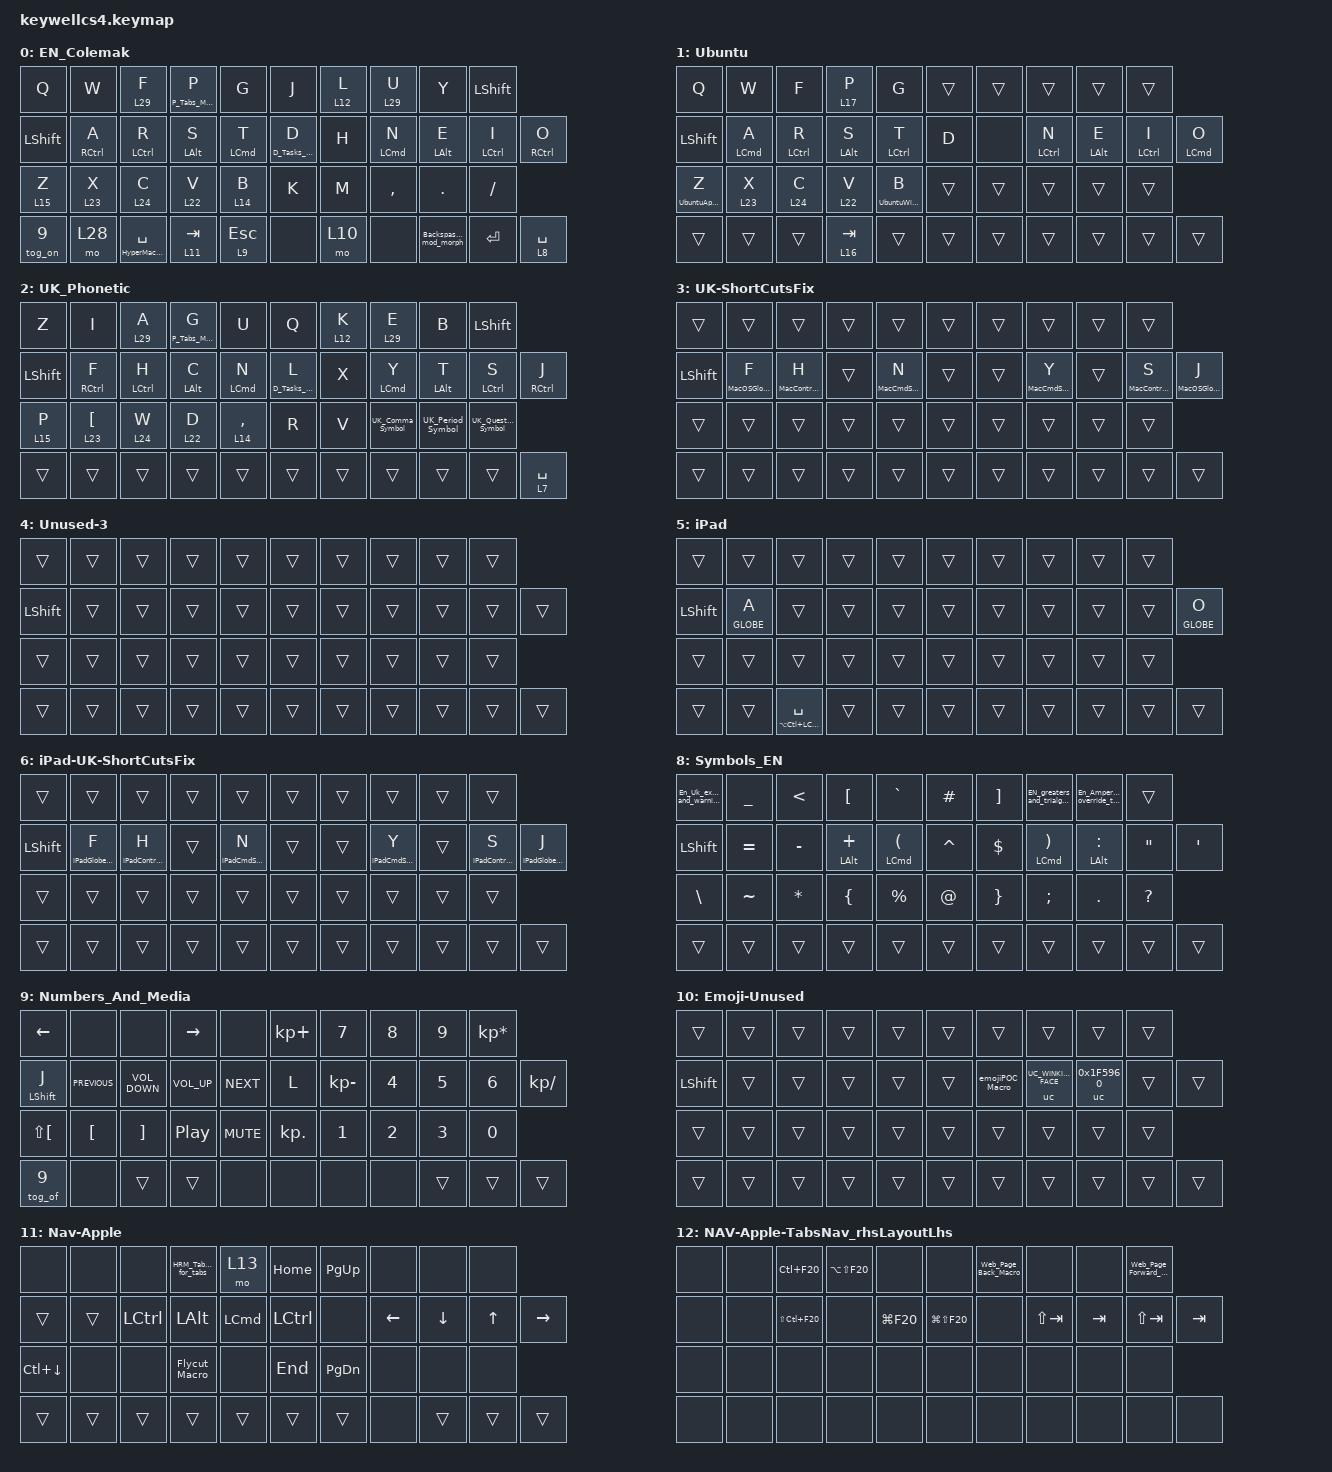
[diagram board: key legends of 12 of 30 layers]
/*
 * Copyright (c) 2020 The ZMK Contributors
 *
 * SPDX-License-Identifier: MIT
 */
// #include <dt-bindings/zmk/rgb.h>
// rob"s zmk unicode

#include <behaviors/unicode.dtsi>

/* MEH...
    Keycodes for other locales
    Gives nothing extra except key representation in visual editor
    https://github.com/nickcoutsos/keymap-editor/wiki/Keycodes-for-other-locales
*/
// #include "includes/keys_uk_enhanced.h"

#define DEFAULT 0
#define SYMBOLS_LAYER  1
#define WARP  22
#define PRESISION  23

#include "includes/mouse.dtsi"
#include <zmk-unicode/keys-extra.h> // All Unicode glyphs except CJK
#include <behaviors.dtsi>
#include <dt-bindings/zmk/bt.h>
#include <dt-bindings/zmk/keys.h>
#include <dt-bindings/zmk/outputs.h>
#include <dt-bindings/zmk/pointing.h>

// rob"s zmk unicode

&uc {
    default-mode = <UC_MODE_MACOS>;
    minimum-length = <4>;
    macos-key = <LALT>;

    // linux-key = <LC(LS(U))>;
    // win-compose-key = <RALT>;
};

/ {
    behaviors {
        #include "includes/open_app_tap_dances.dtsi"

        hml: hml {
            compatible = "zmk,behavior-hold-tap";
            label = "HML";
            bindings = <&kp>, <&kp>;

            #binding-cells = <2>;
            flavor = "balanced";
            tapping-term-ms = <280>;
            quick-tap-ms = <175>;
            require-prior-idle-ms = <150>;
            hold-trigger-key-positions = <5 6 7 8 9 15 16 17 18 19 25 26 27 28 29 30 31 32 33 34 35 36 39 37 38 37 38 40 41 20>;
            hold-trigger-on-release;
        };

        hmr: hmr {
            compatible = "zmk,behavior-hold-tap";
            label = "HMR";
            bindings = <&kp>, <&kp>;

            #binding-cells = <2>;
            flavor = "balanced";
            tapping-term-ms = <280>;
            quick-tap-ms = <175>;
            require-prior-idle-ms = <150>;
            hold-trigger-on-release;
            hold-trigger-key-positions = <0 1 2 3 4 10 11 12 13 14 21 22 23 24 31 32 33 34 35 36 37 38 39 40 41 25 15>;
        };

        Layer_Tap_Timeless_Left: Layer_Tap_Timeless_Left {
            compatible = "zmk,behavior-hold-tap";
            label = "LAYER_TAP_TIMELESS_LEFT";
            bindings = <&mo>, <&kp>;

            #binding-cells = <2>;
            flavor = "balanced";
            tapping-term-ms = <280>;
            quick-tap-ms = <175>;
            require-prior-idle-ms = <150>;
            hold-trigger-on-release;
            hold-trigger-key-positions = <5 6 7 8 9 16 17 18 19 20 26 27 28 29 30 36 37 38 39 40 41 14 11 12 13>;
        };

        Backspase_MacLike_mod_morph: maclike_backspace_delete {
            compatible = "zmk,behavior-mod-morph";
            #binding-cells = <0>;
            bindings = <&kp BACKSPACE>, <&kp DELETE>;

            mods = <(MOD_LSFT)>;   // when LEFT_SHIFT is held
            keep-mods = <0>;       // don't send Shift with Delete
        };

        UK_Period_Symbol: UK_Period_Symbol {
            // Keep it consistent with EN first register only. Second  - ppo.

            compatible = "zmk,behavior-mod-morph";
            label = "UK_PERIOD_SYMBOL";
            bindings = <&kp SLASH>, <&none>;

            #binding-cells = <0>;
            keep-mods = <(MOD_LCTL | MOD_LSFT | MOD_LALT | MOD_LGUI)>;
            mods = <(MOD_RSFT | MOD_LSFT)>;
        };

        UK_Comma_Symbol: UK_Comma_Symbol {
            //  Keep it consistent with EN first register only. Second  - ppo

            compatible = "zmk,behavior-mod-morph";
            label = "UK_COMMA_SYMBOL";
            bindings = <&kp LS(SLASH)>, <&none>;

            #binding-cells = <0>;
            keep-mods = <(MOD_LCTL | MOD_LALT | MOD_LGUI | MOD_LSFT)>;
            mods = <(MOD_LCTL)>;
        };

        UK_Question_Symbol: UK_Question_Symbol {
            //  Keep it consistent with EN 1st and 2nd registers

            compatible = "zmk,behavior-mod-morph";
            label = "UK_QUESTION_SYMBOL";
            bindings = <&kp LC(LA(SLASH))>, <&kp LA(NUMBER_7)>;

            #binding-cells = <0>;
            mods = <(MOD_LSFT | MOD_RSFT)>;
        };

        kt_on: key_toggle_on_only {
            compatible = "zmk,behavior-key-toggle";
            #binding-cells = <1>;
            toggle-mode = "on";   // only presses, never releases
        };

        kt_off: key_toggle_off_only {
            compatible = "zmk,behavior-key-toggle";
            #binding-cells = <1>;
            toggle-mode = "off";  // only releases, never presses
        };

        tog_on: toggle_layer_on_only {
            compatible = "zmk,behavior-toggle-layer";
            #binding-cells = <1>;
            display-name = "Toggle Layer On";
            toggle-mode = "on";
        };

        tog_of: toggle_layer_of_only {
            compatible = "zmk,behavior-toggle-layer";
            #binding-cells = <1>;
            display-name = "Toggle Layer On";
            toggle-mode = "off";
        };

        HyperMac_HT_Timeless: holdTapMacroKp {
            compatible = "zmk,behavior-hold-tap";
            label = "Hyper";
            bindings = <&HyperMacTimeless_Macro>, <&kp>;

            #binding-cells = <2>;
            tapping-term-ms = <173>;
            hold-trigger-key-positions = <0 1 2 3 4 5 6 7 8 9 10 11 12 13 14 15 16 17 18 19 20 21 22 23 24 25 26 27 28 29 30 31 32 33 34 35 36 37 38 39 40 41>;
        };

        MacOS_CMD_non_en_fix_LHRM: MacOS_CMD_non_en_fix_LHRM {
            compatible = "zmk,behavior-hold-tap";
            label = "MACOS_CMD_NON_EN_FIX_LHRM";
            bindings = <&MacCmdShortcutsNonEN_WA_Macro>, <&kp>;

            #binding-cells = <2>;
            flavor = "balanced";
            tapping-term-ms = <180>;
            quick-tap-ms = <175>;
            require-prior-idle-ms = <150>;
            hold-trigger-on-release;
            hold-trigger-key-positions = <5 6 7 8 15 16 17 18 25 26 27 28 36 37 38 39 40 41 30 31 32 33 34 35 9 19 29>;
        };

        MacOS_CMD_non_en_fix_RHRM: MacOS_CMD_non_en_fix_RHRM {
            compatible = "zmk,behavior-hold-tap";
            label = "MACOS_CMD_NON_EN_FIX_RHRM";
            bindings = <&MacCmdShortcutsNonEN_WA_Macro>, <&kp>;

            #binding-cells = <2>;
            flavor = "balanced";
            tapping-term-ms = <180>;
            quick-tap-ms = <175>;
            require-prior-idle-ms = <150>;
            hold-trigger-on-release;
            hold-trigger-key-positions = <0 1 2 3 4 10 11 12 13 14 21 22 23 24 31 32 33 34 35 36 37 38 39 40 41 30 25 15 20>;
        };

        MacOS_Control_non_en_fix_LHRM: MacOS_Control_non_en_fix_LHRM {
            compatible = "zmk,behavior-hold-tap";
            label = "MACOS_CONTROL_NON_EN_FIX_LHRM";
            #binding-cells = <2>;
            flavor = "balanced";
            tapping-term-ms = <180>;
            quick-tap-ms = <175>;
            require-prior-idle-ms = <150>;
            hold-trigger-on-release;
            hold-trigger-key-positions = <5 6 7 8 15 16 17 18 25 26 27 28 36 37 38 39 40 41 30 31 32 33 34 35 9 19 29>;
            bindings = <&MacControlShrtctNonEN_WA_Macro>, <&kp>;
        };

        MacOS_Control_non_en_fix_RHRM: MacOS_Control_non_en_fix_RHRM {
            compatible = "zmk,behavior-hold-tap";
            label = "MACOS_CONTROL_NON_EN_FIX_RHRM";
            #binding-cells = <2>;
            flavor = "balanced";
            tapping-term-ms = <180>;
            quick-tap-ms = <175>;
            require-prior-idle-ms = <150>;
            hold-trigger-on-release;
            bindings = <&MacControlShrtctNonEN_WA_Macro>, <&kp>;

            hold-trigger-key-positions = <0 1 2 3 4 10 11 12 13 14 20 21 22 23 24 30 31 32 33 34 35 36 37 38 39 40 41>;
        };

        iOS_CMD_non_qwerty_fix_LHRM: iOS_CMD_non_qwerty_fix_LHRM {
            compatible = "zmk,behavior-hold-tap";
            label = "IOS_CMD_NON_QWERTY_FIX_LHRM";
            #binding-cells = <2>;
            flavor = "balanced";
            tapping-term-ms = <180>;
            quick-tap-ms = <175>;
            require-prior-idle-ms = <150>;
            hold-trigger-on-release;
            hold-trigger-key-positions = <5 6 7 8 15 16 17 18 25 26 27 28 36 37 38 39 40 41 30 31 32 33 34 35 9 19 29 5>;
            bindings = <&iPadCmdShortcutsNonQwerty_WA>, <&kp>;
        };

        iOS_CMD_non_qwerty_fix_RHRM: iOS_CMD_non_qwerty_fix_RHRM {
            compatible = "zmk,behavior-hold-tap";
            label = "IOS_CMD_NON_QWERTY_FIX_RHRM";
            #binding-cells = <2>;
            flavor = "balanced";
            tapping-term-ms = <180>;
            quick-tap-ms = <175>;
            require-prior-idle-ms = <150>;
            hold-trigger-on-release;
            bindings = <&iPadCmdShortcutsNonQwerty_WA>, <&kp>;

            hold-trigger-key-positions = <0 1 2 3 4 10 11 12 13 14 20 21 22 23 24 30 31 32 33 34 35 36 37 38 39 40 41>;
        };

        iOS_Control_non_qwerty_fix_LHRM: iOS_Control_non_qwerty_fix_LHRM {
            compatible = "zmk,behavior-hold-tap";
            label = "IOS_CONTROL_NON_QWERTY_FIX_LHRM";
            #binding-cells = <2>;
            flavor = "balanced";
            tapping-term-ms = <180>;
            quick-tap-ms = <175>;
            require-prior-idle-ms = <150>;
            hold-trigger-on-release;
            bindings = <&iPadControlShortcutNonQwerty_WA>, <&kp>;

            hold-trigger-key-positions = <5 6 7 8 9 15 16 17 18 19 25 26 27 28 29 36 37 38 39 40 41 30 31 32 33 34 35>;
        };

        iOS_Control_non_qwerty_fix_RHRM: iOS_Control_non_qwerty_fix_RHRM {
            compatible = "zmk,behavior-hold-tap";
            label = "IOS_CONTROL_NON_QWERTY_FIX_RHRM";
            #binding-cells = <2>;
            flavor = "balanced";
            tapping-term-ms = <180>;
            quick-tap-ms = <175>;
            require-prior-idle-ms = <150>;
            hold-trigger-on-release;
            bindings = <&iPadControlShortcutNonQwerty_WA>, <&kp>;

            hold-trigger-key-positions = <0 1 2 3 4 10 11 12 13 14 20 21 22 23 24 30 31 32 33 34 35 36 37 38 39 40 41>;
        };

        MacOS_Globe_non_en_fix_LHRM: MacOS_Globe_non_en_fix_LHRM {
            compatible = "zmk,behavior-hold-tap";
            label = "MACOS_GLOBE_NON_EN_FIX_LHRM";
            #binding-cells = <2>;
            flavor = "balanced";
            tapping-term-ms = <180>;
            quick-tap-ms = <175>;
            require-prior-idle-ms = <150>;
            hold-trigger-on-release;
            hold-trigger-key-positions = <5 6 7 8 15 16 17 18 25 26 27 28 36 37 38 39 40 41 30 31 32 33 34 35 9 19 29>;
            bindings = <&MacOSGlobeShortcutsNonEN_WA>, <&kp>;
        };

        MacOS_Globe_non_en_fix_RHRM: MacOS_Globe_non_en_fix_RHRM {
            compatible = "zmk,behavior-hold-tap";
            label = "MACOS_GLOBE_NON_EN_FIX_RHRM";
            #binding-cells = <2>;
            flavor = "balanced";
            tapping-term-ms = <180>;
            quick-tap-ms = <175>;
            require-prior-idle-ms = <150>;
            hold-trigger-on-release;
            bindings = <&MacOSGlobeShortcutsNonEN_WA>, <&kp>;

            hold-trigger-key-positions = <0 1 2 3 4 10 11 12 13 14 20 21 22 23 24 30 31 32 33 34 35 36 37 38 39 40 41>;
        };

        iOS_Globe_non_qwerty_fix_LHRM: iOS_Globe_non_qwerty_fix_LHRM {
            compatible = "zmk,behavior-hold-tap";
            label = "IOS_GLOBE_NON_QWERTY_FIX_LHRM";
            #binding-cells = <2>;
            flavor = "balanced";
            tapping-term-ms = <180>;
            quick-tap-ms = <175>;
            require-prior-idle-ms = <150>;
            hold-trigger-on-release;
            bindings = <&iPadGlobeShortcutNonQwerty_WA>, <&kp>;

            hold-trigger-key-positions = <5 6 7 8 9 15 16 17 18 19 25 26 27 28 29 36 37 38 39 40 41 30 31 32 33 34 35>;
        };

        iOS_Globe_non_qwerty_fix_RHRM: iOS_Globe_non_qwerty_fix_RHRM {
            compatible = "zmk,behavior-hold-tap";
            label = "IOS_GLOBE_NON_QWERTY_FIX_RHRM";
            #binding-cells = <2>;
            flavor = "balanced";
            tapping-term-ms = <180>;
            quick-tap-ms = <175>;
            require-prior-idle-ms = <150>;
            hold-trigger-on-release;
            bindings = <&iPadGlobeShortcutNonQwerty_WA>, <&kp>;

            hold-trigger-key-positions = <0 1 2 3 4 10 11 12 13 14 20 21 22 23 24 30 31 32 33 34 35 36 37 38 39 40 41>;
        };

        D_Tasks_Timeless_left: D_Tasks_Timeless_left {
            compatible = "zmk,behavior-hold-tap";
            label = "D_TASKS_TIMELESS_LEFT";
            bindings = <&D_Tasks_Macro>, <&kp>;

            #binding-cells = <2>;
            flavor = "balanced";
            tapping-term-ms = <280>;
            quick-tap-ms = <175>;
            require-prior-idle-ms = <150>;
            hold-trigger-key-positions = <5 6 7 8 9 16 17 18 19 26 27 28 29 30 31 32 33 34 35 36 39 37 38 37 38 40 41 20>;
            hold-trigger-on-release;
        };

        UbuntuAppSwWA_Timeless: UbuntuAppSwWA_Timeless {
            compatible = "zmk,behavior-hold-tap";
            label = "UBUNTUAPPSWWA_TIMELESS";
            bindings = <&UbuntuAppSwWA_Macro>, <&kp>;

            #binding-cells = <2>;
            flavor = "balanced";
            tapping-term-ms = <280>;
            quick-tap-ms = <175>;
            require-prior-idle-ms = <150>;
            hold-trigger-key-positions = <5 6 7 8 9 16 17 18 19 26 27 28 29 30 31 32 33 34 35 36 39 37 38 37 38 40 41 20>;
            hold-trigger-on-release;
        };

        P_Tabs_Timeless_left: P_Tabs_Timeless_left {
            compatible = "zmk,behavior-hold-tap";
            label = "P_TABS_TIMELESS_LEFT";
            bindings = <&P_Tabs_Macro>, <&kp>;

            #binding-cells = <2>;
            flavor = "balanced";
            tapping-term-ms = <280>;
            quick-tap-ms = <175>;
            require-prior-idle-ms = <150>;
            hold-trigger-key-positions = <5 6 7 8 9 16 17 18 19 26 27 28 29 30 31 32 33 34 35 36 39 37 38 37 38 40 41 20>;
            hold-trigger-on-release;
        };

        Layer_Tap_Timeless_Right: Layer_Tap_Timeless_Right {
            compatible = "zmk,behavior-hold-tap";
            label = "LAYER_TAP_TIMELESS_RIGHT";
            bindings = <&mo>, <&kp>;

            #binding-cells = <2>;
            flavor = "balanced";
            tapping-term-ms = <280>;
            quick-tap-ms = <175>;
            require-prior-idle-ms = <150>;
            hold-trigger-on-release;
            hold-trigger-key-positions = <0 1 2 3 4 10 11 12 13 14 15 21 22 23 24 25 31 32 34 35 33>;
        };

        UbuntuWindowsSwWA: UbuntuWindowsSwWA {
            compatible = "zmk,behavior-hold-tap";
            label = "UBUNTUWINDOWSSWWA";
            bindings = <&UbuntuWindowsSwWA_Macro>, <&kp>;

            #binding-cells = <2>;
            flavor = "balanced";
            tapping-term-ms = <280>;
            quick-tap-ms = <175>;
            require-prior-idle-ms = <150>;
            hold-trigger-key-positions = <5 6 7 8 9 16 17 18 19 26 27 28 29 30 31 32 33 34 35 36 39 37 38 37 38 40 41 20>;
            hold-trigger-on-release;
        };

        Thumb_HT_VeryShort: Thumb_HT_VeryShort {
            compatible = "zmk,behavior-hold-tap";
            label = "THUMB_HT_VERYSHORT";
            bindings = <&mo>, <&kp>;

            #binding-cells = <2>;
            tapping-term-ms = <120>;
            hold-trigger-key-positions = <0 1 2 3 4 5 6 7 8 9 10 11 12 13 14 15 16 17 18 19 20 21 22 23 24 25 26 27 28 29 30 31 32 33 34 35 36 37 38 39 40 41>;
            quick-tap-ms = <175>;
            flavor = "balanced";
            hold-trigger-on-release;
        };

        Sticky_1500ms: Sticky_1500ms {
            compatible = "zmk,behavior-sticky-key";
            label = "STICKY_1500MS";
            bindings = <&kp>;
            #binding-cells = <1>;
            release-after-ms = <1500>;
        };

        Thumb_HT_Normal: Thumb_HT_Normal {
            compatible = "zmk,behavior-hold-tap";
            label = "THUMB_HT_NORMAL";
            bindings = <&mo>, <&kp>;

            #binding-cells = <2>;
            tapping-term-ms = <178>;
            hold-trigger-key-positions = <0 1 2 3 4 5 6 7 8 9 10 11 12 13 14 15 16 17 18 19 20 21 22 23 24 25 26 27 28 29 30 31 32 33 34 35 36 37 38 39 40 41>;
            quick-tap-ms = <175>;
            flavor = "balanced";
            hold-trigger-on-release;
        };

        En_Ampersan_override_tied_Shift: En_Ampersan_override_tied_Shift {
            compatible = "zmk,behavior-mod-morph";
            label = "EN_AMPERSAN_OVERRIDE_TIED_SHIFT";
            bindings = <&kp AMPS>, <&kp N7>;

            #binding-cells = <0>;
            keep-mods = <(MOD_LSFT|MOD_LALT|MOD_RSFT|MOD_RALT)>;
            mods = <(MOD_LSFT|MOD_RSFT|MOD_LALT|MOD_RALT)>;
        };

        Uk_Ampersan_override_tied_Shift: Uk_Ampersan_override_tied_Shift {
            compatible = "zmk,behavior-mod-morph";
            label = "UK_AMPERSAN_OVERRIDE_TIED_SHIFT";
            bindings = <&kp LA(LC(LS(N7)))>, <&kp N7>;

            #binding-cells = <0>;
            keep-mods = <(MOD_LSFT|MOD_LALT|MOD_RSFT|MOD_RALT)>;
            mods = <(MOD_LSFT|MOD_RSFT|MOD_LALT|MOD_RALT)>;
        };

        EN_greaters_and_trialgles: EN_greaters_and_trialgles {
            compatible = "zmk,behavior-mod-morph";
            label = "EN_GREATERS_AND_TRIALGLES";
            bindings = <&kp GREATER_THAN>, <&kp KP_NUMBER_1>;

            #binding-cells = <0>;
            keep-mods = <(MOD_LSFT|MOD_LALT|MOD_RSFT|MOD_RALT)>;
            mods = <(MOD_LSFT|MOD_RSFT|MOD_LALT|MOD_RALT)>;
        };

        En_Uk_exclamation_and_warning: En_Uk_exclamation_and_warning {
            compatible = "zmk,behavior-mod-morph";
            label = "EN_UK_EXCLAMATION_AND_WARNING";
            bindings = <&kp EXCL>, <&kp NUMBER_1>;

            #binding-cells = <0>;
            keep-mods = <(MOD_LSFT|MOD_LALT|MOD_RSFT|MOD_RALT)>;
            mods = <(MOD_LSFT|MOD_RSFT|MOD_LALT|MOD_RALT)>;
        };

        leaderKey_1: leaderKey_1 {
            compatible = "zmk,behavior-leader-key";
            #binding-cells = <0>;

            KeyCluShowShortcutsFix {
                sequence = <S H O>;
                bindings = <&KeyCluShowShortcutsMacro>;
            };
        };
    };

    combos {
        compatible = "zmk,combos";

        #include "includes/cyrillic_letters_combos.dtsi"

        combo_CmdTAbAppSW {
            bindings = <&CmdTAbAppSW_Macro>;
            key-positions = <34 25>;
            layers = <0 1 2 3 4 5 6>;
            timeout-ms = <150>;
        };

        Mac_OneHanded_Sticky_Command {
            bindings = <&Sticky_1500ms LEFT_COMMAND>;
            key-positions = <24 23>;
            layers = <0 2 3 4 7 6 9 7 8 10 11 12 13 14 15>;
        };

        Ubuntu_OneHanded_Sticky_Control {
            bindings = <&Sticky_1500ms LEFT_CONTROL>;
            key-positions = <24 23>;
            layers = <1>;
        };

        Mac_SwitchToUK {
            //  Should only possible when Ukrainian language is in use (i.e. combo active on Ua shortcuts fix layer is on).
            //  On this depends syncronized swithcing of OS language & ZMK layouts for iPad

            bindings = <&MacKarabinerUK_Macro>;
            key-positions = <28 29>;
            layers = <0>;
            timeout-ms = <170>; // must be less than hold-tap of a key that used both in hold-tap and combo. Or there will be race conditions and WATs.
        };

        Mac_SwitchToEN {
            //  Should only possible when Englist language is in use (i.e. combo active on Colemac layer only).
            //  On this depends syncronized swithcing of OS language & ZMK layouts for iPad

            bindings = <&MacKarabinerEN_Macro>;
            key-positions = <27 28>;
            layers = <3>;
            timeout-ms = <170>; // must be less than hold-tap of a key that used both in hold-tap and combo. Or there will be race conditions and WATs.
        };

        Mac_ENSupresLetterDrop {
            // when En Seleced, combo to switch to EN disabled. When you blindly hit keys of this combo, to ensure you
            // on EN, being on EN already, itnsead of combo you get letters typed. This is annoying to delete then.
            // So suppress these combination of letters, by having them in a same combo as EN but producing nothing.

            bindings = <&none>;
            key-positions = <28 27>;
            timeout-ms = <170>;
            layers = <0>;
        };

        Mac_UK_Accent_DeadKey {
            // Second role is Supressor for Ua/Uk. Read in other's conterpart combos. Either not delete, or implement then
            // this role elswere.

            bindings = <&kp LA(KP_NUMBER_0)>;
            key-positions = <28 29>;
            timeout-ms = <170>;
            layers = <3>;
        };

        iPad_SwitchToEN {
            // Read in Mac counterpat combo

            bindings = <&iPadEN_Macro>;
            key-positions = <27 28>;
            timeout-ms = <190>; // must be less than hold-tap of a key that used both in hold-tap and combo. Or there will be race conditions and WATs
            layers = <6>;
        };

        iPad_SwitchToUK {
            // Read in Mac counterpat combo

            bindings = <&iPadUK_Macro>;
            key-positions = <28 29>;
            timeout-ms = <190>; // must be less than hold-tap of a key that used both in hold-tap and combo. Or there will be race conditions and WATs
            layers = <5>;
        };

        iPadENSupresWhenAlready {
            // read mac counterpart combos or search "supress"

            bindings = <&none>;
            key-positions = <28 27>;
            timeout-ms = <190>;
            layers = <5>;
        };

        iPadUKSupressWhenAlready {
            // read mac counterpart combos or search "supress"

            bindings = <&none>;
            key-positions = <28 29>;
            timeout-ms = <190>;
            layers = <6>;
        };

        Delete_Word_Mac {
            bindings = <&kp LA(BACKSPACE)>;
            key-positions = <17 18>;
            layers = <0 2 3 5 4 6>;
            require-prior-idle-ms = <320>;
        };

        Delete_Word_Ubuntu {
            bindings = <&kp LC(BACKSPACE)>;
            key-positions = <17 18>;
            layers = <1>;
            require-prior-idle-ms = <320>;
        };

        AppWindowsSwNext1 {
            bindings = <&kp LG(GRAVE)>;
            key-positions = <21 14>;
            timeout-ms = <150>;
            layers = <0 1 2 3 4 5 6>;
        };

        AppWindowsSwPrevP1 {
            bindings = <&kp LG(LS(GRAVE))>;
            key-positions = <21 11>;
            timeout-ms = <150>;
            layers = <0 1 2 3 4 5 6>;
        };

        AppWindowsSwPrevP2 {
            bindings = <&kp LG(LS(GRAVE))>;
            key-positions = <21 12>;
            timeout-ms = <150>;
            layers = <0 1 2 3 4 5 6>;
        };

        AppWindowsSwNextP2 {
            bindings = <&kp LG(GRAVE)>;
            key-positions = <21 13>;
            timeout-ms = <150>;
            layers = <0 1 2 3 4 5 6>;
        };

        MediaLayerStickLikeWP {
            bindings = <&to 9>;
            key-positions = <1 3>;
            timeout-ms = <150>;
            layers = <9>;
        };

        AND {
            bindings = <&AND_macro>;
            key-positions = <7 8>;
            layers = <8 7>;
        };

        OR {
            bindings = <&OR_Macro>;
            key-positions = <21 22>;
            layers = <8 7>;
            timeout-ms = <100>;
        };

        PutWordInQuotes {
            bindings = <&PutWordInQuotes_Macro>;
            key-positions = <19 18>;
            layers = <8 7>;
        };

        KeyCluShowShortcutsLeftCombo {
            bindings = <&leaderKey_1>;
            key-positions = <20 11>;
            layers = <0 1 2 3 6 5>;
        };
    };

    macros {
        #include "includes/open_app_shortcuts_macros.dtsi"

        CmdTAbAppSW_Macro: CmdTAbReleaseTabCombo {
            //    - ! Don't asign to holds of hold-taps as in standard user press CMD+TAB faster and it will not trigger in time
            //    - wait and tap time of at least 30ms is recommended to avoid having HID notifications grouped at the BLE
            //  protocol level and then processed out of order

            compatible = "zmk,behavior-macro";
            #binding-cells = <0>;
            bindings =
                <&macro_press>,
                <&kp LCMD &mo 11 &kp TAB>,
                <&macro_wait_time 100>,
                <&macro_release>,
                <&kp TAB>,
                <&macro_wait_time 1>,
                <&macro_pause_for_release>,
                <&macro_release>,
                <&mo 11 &kp LCMD>;

            label = "CMDTABRELEASETABCOMBO";
            tap-ms = <1>;  // not used as no taps
            wait-ms = <1>;  // make initial cmd press down asap
        };

        emojiPOC_Macro: emojiNum1 {
            compatible = "zmk,behavior-macro";
            #binding-cells = <0>;
            bindings = <&kp S &kp M &kp I &kp L &kp E &kp N &kp U &kp M>;
            label = "EMOJINUM1";
            wait-ms = <0>;
            tap-ms = <0>;
        };

        Mac_Macro: Mac {
            compatible = "zmk,behavior-macro";
            tap-ms = <0>;
            wait-ms = <0>;
            #binding-cells = <0>;
            bindings = <&bt BT_SEL 0 &tog_of 1 &tog_of 2 &tog_of 3 &tog_of 5 &tog_of 6 &bt BT_DISC 1 &bt BT_DISC 2 &bt BT_DISC 3 &bt BT_DISC 4>;
            label = "MAC";
        };

        iPad_Macro: iPad {
            compatible = "zmk,behavior-macro";
            tap-ms = <0>;
            wait-ms = <0>;
            #binding-cells = <0>;
            bindings = <&bt BT_SEL 1 &tog_of 1 &tog_of 2 &tog_of 3 &tog_on 5 &tog_of 6 &bt BT_DISC 0 &bt BT_DISC 2 &bt BT_DISC 3 &bt BT_DISC 4>;
            label = "IPAD";
        };

        Ubuntu_Macro: UbuntuMacro {
            compatible = "zmk,behavior-macro";
            tap-ms = <0>;
            wait-ms = <0>;
            #binding-cells = <0>;
            bindings = <&bt BT_SEL 2 &tog_of 2 &tog_of 3 &tog_of 5 &tog_of 6 &bt BT_DISC 0 &bt BT_DISC 1 &bt BT_DISC 3 &bt BT_DISC 4 &tog_on 1>;
            label = "UBUNTUMACRO";
        };

        HyperMacTimeless_Macro: HyperMacTimelessMacro {
            // Supports hyper by standing it above hrm layer. ie swithes to plain letters + hyperKey

            compatible = "zmk,behavior-macro";
            label = "HYPERMACTIMELESSMACRO";
            #binding-cells = <0>;
            tap-ms = <0>;
            wait-ms = <0>;
            bindings =
                <&macro_press>,
                <&mo 27>,
                <&macro_press>,
                <&kp F16>,
                <&macro_pause_for_release>,
                <&macro_release>,
                <&mo 27>,
                <&macro_release>,
                <&kp F16>;
        };

        MacCmdShortcutsNonEN_WA_Macro: MacOSCmdShortcutsNonEN_WA {
            // f21/F22 - if you want have regular keyboard change layouts to a particular with Bigram/Hyper Layer - make it separete shortcut (like ol' LE / LU) ^16499de1

            compatible = "zmk,behavior-macro";
            label = "MACOSCMDSHORTCUTSNONEN_WA";
            tap-ms = <0>;
            wait-ms = <0>;
            #binding-cells = <0>;
            bindings =
                <&tog_of 2 &tog_of 3 &kt_on LCMD>,
                <&macro_pause_for_release>,
                <&kt_off LCMD &tog_on 2 &tog_on 3>;
        };

        MacControlShrtctNonEN_WA_Macro: ControlShortcutsNonEN_WA {
            // read ^16499de1

            compatible = "zmk,behavior-macro";
            label = "CONTROLSHORTCUTSNONEN_WA";
            tap-ms = <0>;
            wait-ms = <0>;
            #binding-cells = <0>;
            bindings =
                <&tog_of 2 &tog_of 3 &kt_on LEFT_CONTROL>,
                <&macro_pause_for_release>,
                <&kt_off LEFT_CONTROL &tog_on 2 &tog_on 3>;
        };

        MacKarabinerUK_Macro: MacKarabinerUK {
            /*
			Macro is mandatory. As keyboard must switch layout too (in addition to sending langeage changing key sequence
			to karabener which is possible wo macro)

			For rdp/vnc/remote Karabiner doesn't work. To switch system layouts remotely bypass karabiner.
			For example by using Apple Script added as a service with shortcut.
		*/

            compatible = "zmk,behavior-macro";
            tap-ms = <0>;
            wait-ms = <0>;
            #binding-cells = <0>;
            bindings = <&kp F22 &tog_on 2 &tog_on 3>;
            label = "MACKARABINERUK";
        };

        MacKarabinerEN_Macro: MacKarabinerEN {
            // read ^16499de1

            compatible = "zmk,behavior-macro";
            tap-ms = <0>;
            wait-ms = <0>;
            #binding-cells = <0>;
            bindings = <&kp F21 &tog_of 2 &tog_of 3>;
            label = "MACKARABINEREN";
        };

        iPadUK_Macro: iPadUK_Macro {
            compatible = "zmk,behavior-macro";
            tap-ms = <0>;
            wait-ms = <0>;
            #binding-cells = <0>;
            bindings = <&kp CAPSLOCK &tog_on 2 &tog_on 6>;
            label = "IPADUKMACRO";
        };

        iPadEN_Macro: iPadEN_Macro {
            tap-ms = <0>;
            wait-ms = <0>;
            compatible = "zmk,behavior-macro";
            #binding-cells = <0>;
            bindings = <&kp CAPSLOCK &tog_of 2 &tog_of 6>;
            label = "IPADENMACRO";
        };

        iPadCmdShortcutsNonQwerty_WA: CmdShortcutsNonQwerty_WA {
            compatible = "zmk,behavior-macro";
            tap-ms = <0>;
            wait-ms = <0>;
            #binding-cells = <0>;
            bindings =
                <&tog_of 6 &tog_of 2 &kt_on LCMD>,
                <&macro_pause_for_release>,
                <&tog_on 6 &tog_on 2 &kt_off LCMD>;

            label = "CMDSHORTCUTSNONQWERTY_WA";
        };

        iPadControlShortcutNonQwerty_WA: iPadControlShortcutNonQwerty_WA {
            compatible = "zmk,behavior-macro";
            tap-ms = <0>;
            wait-ms = <0>;
            #binding-cells = <0>;
            bindings =
                <&tog_of 6 &tog_of 2 &kt_on LEFT_CONTROL>,
                <&macro_pause_for_release>,
                <&tog_on 6 &tog_on 2 &kt_off LEFT_CONTROL>;

            label = "IPADCONTROLSHORTCUTNONQWERTY_WA";
        };

        MacOSGlobeShortcutsNonEN_WA: MacOSGlobeShortcutsNonEN_WA {
            // read ^16499de1

            compatible = "zmk,behavior-macro";
            tap-ms = <0>;
            wait-ms = <0>;
            #binding-cells = <0>;
            bindings =
                <&tog_of 2 &tog_of 3 &kt_on RIGHT_CONTROL>,
                <&macro_pause_for_release>,
                <&kt_off RIGHT_CONTROL &tog_on 2 &tog_on 3>;

            label = "MACOSGLOBESHORTCUTSNONEN_WA";
        };

        iPadGlobeShortcutNonQwerty_WA: iPadGlobeShortcutNonQwerty_WA {
            compatible = "zmk,behavior-macro";
            tap-ms = <0>;
            wait-ms = <0>;
            #binding-cells = <0>;
            bindings =
                <&tog_of 6 &tog_of 2 &kt_on GLOBE>,
                <&macro_pause_for_release>,
                <&tog_on 6 &tog_on 2 &kt_off GLOBE>;

            label = "IPADGLOBESHORTCUTNONQWERTY_WA";
        };

        UbuntuWindowsSwWA_Macro: www {
            compatible = "zmk,behavior-macro";
            tap-ms = <0>;
            wait-ms = <0>;
            #binding-cells = <0>;
            bindings =
                <&kt_on RIGHT_ALT &tog_on 19>,
                <&macro_pause_for_release>,
                <&kt_off RIGHT_ALT &tog_of 19>;

            label = "WWW";
        };

        UbuntuAppSwWA_Macro: vvvv {
            compatible = "zmk,behavior-macro";
            #binding-cells = <0>;
            tap-ms = <0>;
            wait-ms = <0>;
            bindings =
                <&kt_on RIGHT_ALT &tog_on 20>,
                <&macro_pause_for_release>,
                <&kt_off RIGHT_ALT &tog_of 20>;

            label = "VVVV";
        };

        D_Tasks_Macro: D_Tasks_Macro {
            compatible = "zmk,behavior-macro";
            label = "D_TASKS_MACRO";
            #binding-cells = <0>;
            tap-ms = <0>;
            wait-ms = <0>;
            bindings =
                <&macro_press>,
                <&mo 9>,
                <&macro_press>,
                <&kp LEFT_CONTROL>,
                <&macro_pause_for_release>,
                <&macro_release>,
                <&mo 9>,
                <&macro_release>,
                <&kp LEFT_CONTROL>;
        };

        P_Tabs_Macro: P_Tabs_Macro {
            compatible = "zmk,behavior-macro";
            label = "P_TABS_MACRO";
            #binding-cells = <0>;
            tap-ms = <0>;
            wait-ms = <0>;
            bindings =
                <&macro_press>,
                <&mo 9>,
                <&macro_press>,
                <&kp LEFT_COMMAND>,
                <&macro_pause_for_release>,
                <&macro_release>,
                <&mo 9>,
                <&macro_release>,
                <&kp LEFT_COMMAND>;
        };

        Flycut_Macro: Flycut {
            compatible = "zmk,behavior-macro";
            tap-ms = <0>;
            wait-ms = <0>;
            #binding-cells = <0>;
            bindings =
                <&kt_on LEFT_ALT &kt LSHFT &kp V &tog_on 11>,
                <&macro_pause_for_release>,
                <&kt_off LEFT_ALT &kt_off LSHFT &tog_of 11>;

            label = "FLYCUT";
        };

        HRM_Tabs_layer_for_tabs: Tabs_Macro {
            compatible = "zmk,behavior-macro";
            tap-ms = <0>;
            wait-ms = <0>;
            #binding-cells = <0>;
            bindings =
                <&kt_on LEFT_CONTROL &tog_on 12>,
                <&macro_pause_for_release>,
                <&kt_off LEFT_CONTROL &tog_of 12>;

            label = "TABS_MACRO";
        };

        Web_Page_Back_Macro: Web_Page_Back {
            compatible = "zmk,behavior-macro";
            tap-ms = <0>;
            wait-ms = <0>;
            #binding-cells = <0>;
            bindings = <&kt_off LEFT_CONTROL &kp LG(LEFT_BRACKET)>;
            label = "WEB_PAGE_BACK";
        };

        Web_Page_Forward_Macro: Web_Page_Forward {
            compatible = "zmk,behavior-macro";
            tap-ms = <0>;
            wait-ms = <0>;
            #binding-cells = <0>;
            bindings = <&kt_off LEFT_CONTROL &kp LG(RIGHT_BRACKET)>;
            label = "WEB_PAGE_FORWARD";
        };

        PutWordInQuotes_Macro: PutInQuotes {
            compatible = "zmk,behavior-macro";
            #binding-cells = <0>;
            bindings = <&kp LA(LEFT_ARROW) &kp DOUBLE_QUOTES &kp LA(RIGHT) &kp DOUBLE_QUOTES &kp SPACE>;
            label = "PUTINQUOTES";
            wait-ms = <0>;
            tap-ms = <0>;
        };

        AND_macro: AND {
            compatible = "zmk,behavior-macro";
            #binding-cells = <0>;
            bindings = <&kp SPACE &kp LS(A) &kp LS(N) &kp LS(D) &kp SPACE>;
            label = "AND";
            wait-ms = <0>;
            tap-ms = <0>;
        };

        OR_Macro: OR_Macro {
            compatible = "zmk,behavior-macro";
            #binding-cells = <0>;
            bindings = <&kp SPACE &kp LS(O) &kp LS(R) &kp SPACE>;
            label = "OR_MACRO";
            wait-ms = <0>;
            tap-ms = <0>;
        };

        KeyCluShowShortcutsMacro: KeyCluShowShortcutsMacro {
            compatible = "zmk,behavior-macro";
            tap-ms = <0>;
            wait-ms = <0>;
            #binding-cells = <0>;
            bindings =
                <&macro_wait_time 300>,
                <&kp RIGHT_SHIFT>,
                <&kp RIGHT_SHIFT>,
                <&kt_on RIGHT_SHIFT>,
                <&macro_wait_time 1000>,
                <&kt_off RIGHT_SHIFT>;
            label = "KEYCLUSHOWSHORTCUTSMACRO";
        };
    };

    keymap {
        compatible = "zmk,keymap";

        EN_Colemak {
            bindings = <
&kp Q                          &kp W                 &Layer_Tap_Timeless_Left 29 F  &P_Tabs_Timeless_left 0 P      &kp G                          &kp J                       &Layer_Tap_Timeless_Right 12 L  &Layer_Tap_Timeless_Right 29 U  &kp Y        &kp LEFT_SHIFT
&kp LEFT_SHIFT                 &hml RIGHT_CONTROL A  &hml LEFT_CONTROL R            &hml LALT S                    &hml LCMD T                    &D_Tasks_Timeless_left 0 D  &kp H                           &hmr LCMD N                     &hmr LALT E  &hmr LEFT_CONTROL I           &hmr RIGHT_CONTROL O
&Layer_Tap_Timeless_Left 15 Z  &lt 23 X              &lt 24 C                       &lt 22 V                       &Layer_Tap_Timeless_Left 14 B  &kp K                       &kp M                           &kp COMMA                       &kp DOT      &kp FSLH
                               &tog_on 9             &mo 28                         &HyperMac_HT_Timeless 0 SPACE  &Thumb_HT_VeryShort 11 TAB     &Thumb_HT_Normal 9 ESCAPE   &none                           &mo 10                          &none        &Backspase_MacLike_mod_morph  &kp ENTER             &Thumb_HT_VeryShort 8 SPACE
            >;
        };

        Ubuntu {
            bindings = <
&kp Q                        &kp W                &kp F                &Layer_Tap_Timeless_Left 17 P  &kp G                   &trans  &trans  &trans               &trans       &trans
&kp LEFT_SHIFT               &hml LEFT_COMMAND A  &hml LEFT_CONTROL R  &hml LALT S                    &hml LEFT_CONTROL T     &kp D   &none   &hmr LEFT_CONTROL N  &hmr LALT E  &hmr LEFT_CONTROL I  &hmr LEFT_COMMAND O
&UbuntuAppSwWA_Timeless 0 Z  &lt 23 X             &lt 24 C             &lt 22 V                       &UbuntuWindowsSwWA 0 B  &trans  &trans  &trans               &trans       &trans
                             &trans               &trans               &trans                         &lt 16 TAB              &trans  &trans  &trans               &trans       &trans               &trans               &trans
            >;
        };

        UK_Phonetic {
            // Keys physically like EN Colemak, but produce UK letters. (while system set to qwerty. this allows to type on devices where only qwerty like remote macr or localy on iPad)

            bindings = <
&kp Z                          &kp I                 &Layer_Tap_Timeless_Left 29 A  &P_Tabs_Timeless_left 0 G  &kp U                              &kp Q                       &Layer_Tap_Timeless_Right 12 K  &Layer_Tap_Timeless_Right 29 E  &kp B              &kp LEFT_SHIFT
&kp LEFT_SHIFT                 &hml RIGHT_CONTROL F  &hml LEFT_CONTROL H            &hml LALT C                &hml LEFT_COMMAND N                &D_Tasks_Timeless_left 0 L  &kp X                           &hmr LEFT_COMMAND Y             &hmr LALT T        &hmr LEFT_CONTROL S  &hmr RIGHT_CONTROL J
&Layer_Tap_Timeless_Left 15 P  &lt 23 LEFT_BRACKET   &lt 24 W                       &lt 22 D                   &Layer_Tap_Timeless_Left 14 COMMA  &kp R                       &kp V                           &UK_Comma_Symbol                &UK_Period_Symbol  &UK_Question_Symbol
                               &trans                &trans                         &trans                     &trans                             &trans                      &trans                          &trans                          &trans             &trans               &trans                &Thumb_HT_VeryShort 7 SPACE
            >;
        };

        UK_Phonetic_MacOS_ShortCuts_Fix {
            display-name = "UK-ShortCutsFix";
            bindings = <
&trans          &trans                            &trans                              &trans  &trans                          &trans  &trans  &trans                          &trans  &trans
&kp LEFT_SHIFT  &MacOS_Globe_non_en_fix_LHRM 0 F  &MacOS_Control_non_en_fix_LHRM 0 H  &trans  &MacOS_CMD_non_en_fix_LHRM 0 N  &trans  &trans  &MacOS_CMD_non_en_fix_RHRM 0 Y  &trans  &MacOS_Control_non_en_fix_RHRM 0 S  &MacOS_Globe_non_en_fix_RHRM 0 J
&trans          &trans                            &trans                              &trans  &trans                          &trans  &trans  &trans                          &trans  &trans
                &trans                            &trans                              &trans  &trans                          &trans  &trans  &trans                          &trans  &trans                              &trans                            &trans
            >;
        };

        Unused-3 {
            display-name = "Unused-3";
            bindings = <
&trans          &trans  &trans  &trans  &trans  &trans  &trans  &trans  &trans  &trans
&kp LEFT_SHIFT  &trans  &trans  &trans  &trans  &trans  &trans  &trans  &trans  &trans  &trans
&trans          &trans  &trans  &trans  &trans  &trans  &trans  &trans  &trans  &trans
                &trans  &trans  &trans  &trans  &trans  &trans  &trans  &trans  &trans  &trans  &trans
            >;
        };

        iPad {
            bindings = <
&trans          &trans        &trans  &trans                          &trans  &trans  &trans  &trans  &trans  &trans
&kp LEFT_SHIFT  &hml GLOBE A  &trans  &trans                          &trans  &trans  &trans  &trans  &trans  &trans  &hmr GLOBE O
&trans          &trans        &trans  &trans                          &trans  &trans  &trans  &trans  &trans  &trans
                &trans        &trans  &mt LA(LC(LEFT_COMMAND)) SPACE  &trans  &trans  &trans  &trans  &trans  &trans  &trans        &trans
            >;
        };

        iPad_UK_Phonetic_Shortcut_WA {
            display-name = "iPad-UK-ShortCutsFix";
            bindings = <
&trans          &trans                              &trans                                &trans  &trans                            &trans  &trans  &trans                            &trans  &trans
&kp LEFT_SHIFT  &iOS_Globe_non_qwerty_fix_LHRM 0 F  &iOS_Control_non_qwerty_fix_LHRM 0 H  &trans  &iOS_CMD_non_qwerty_fix_LHRM 0 N  &trans  &trans  &iOS_CMD_non_qwerty_fix_RHRM 0 Y  &trans  &iOS_Control_non_qwerty_fix_RHRM 0 S  &iOS_Globe_non_qwerty_fix_RHRM 0 J
&trans          &trans                              &trans                                &trans  &trans                            &trans  &trans  &trans                            &trans  &trans
                &trans                              &trans                                &trans  &trans                            &trans  &trans  &trans                            &trans  &trans                                &trans                              &trans
            >;
        };

        Symbols_UK_QWERTY {
            bindings = <
&En_Uk_exclamation_and_warning  &kp UNDER  &kp LC(LA(LS(COMMA)))  &kp LC(LA(LEFT_BRACKET))      &kp LC(LA(GRAVE))                   &kp LA(N3)  &kp LC(LA(RIGHT_BRACKET))      &En_Uk_exclamation_and_warning       &Uk_Ampersan_override_tied_Shift  &trans
&kp LEFT_SHIFT                  &kp EQUAL  &kp MINUS              &hml LALT PLUS                &hml LEFT_COMMAND LEFT_PARENTHESIS  &kp LA(N6)  &kp LA(N4)                     &hmr LEFT_COMMAND RIGHT_PARENTHESIS  &hmr LEFT_ALT LA(LC(COLON))       &kp LC(LA(LS(SINGLE_QUOTE)))  &kp LC(LA(APOSTROPHE))
&kp LA(LC(BACKSLASH))           &kp LA(M)  &kp LA(N8)             &kp LC(LA(LS(LEFT_BRACKET)))  &kp LS(N5)                          &kp LA(N2)  &kp LA(LC(LS(RIGHT_BRACKET)))  &kp LA(LC(SEMI))                     &kp LA(LC(PERIOD))                &kp LA(LS(LC(SLASH)))
                                &trans     &trans                 &trans                        &trans                              &trans      &trans                         &trans                               &trans                            &trans                        &trans                  &trans
            >;
        };

        Symbols_EN {
            //        &hml LEFT_COMMAND LEFT_PARENTHESIS
            //                  is to make CMD-+ shortcut (increase/decrease browrer page) layer- & key-race agnostic.
            //                  So it worked not only when you hit cmd-mo(symbol layer)-kp(+/-) but even
            //                  when you key-rased as mo(symbol layer)- kp(cmd)-kp(+/-). Try with hands and you understand

            bindings = <
&En_Uk_exclamation_and_warning  &kp UNDER  &kp LESS_THAN  &kp LEFT_BRACKET  &kp GRAVE                           &kp HASH   &kp RIGHT_BRACKET  &EN_greaters_and_trialgles           &En_Ampersan_override_tied_Shift  &trans
&kp LEFT_SHIFT                  &kp EQUAL  &kp MINUS      &hml LALT PLUS    &hml LEFT_COMMAND LEFT_PARENTHESIS  &kp CARET  &kp DOLLAR         &hmr LEFT_COMMAND RIGHT_PARENTHESIS  &hmr LALT COLON                   &kp DOUBLE_QUOTES  &kp APOSTROPHE
&kp BACKSLASH                   &kp TILDE  &kp ASTERISK   &kp LEFT_BRACE    &kp PERCENT                         &kp AT     &kp RIGHT_BRACE    &kp SEMI                             &kp PERIOD                        &kp QUESTION
                                &trans     &trans         &trans            &trans                              &trans     &trans             &trans                               &trans                            &trans             &trans          &trans
            >;
        };

        Numbers_And_Media {
            //
            //      ← → Arrows - Youtube, VLC, some online players: skip Fast Forward/Backward/Rewind
            //                   Apple Music: duplicate function of Next/Previous track
            //      J/Shift    - Youtube: Faster Rewind (J)
            //      L          - Youtube: Fast Forward
            //      Shift      - compatibilyty for Scrensot Shortcuts & moving Tabs to N-th Desktop.

            bindings = <
&kp LEFT_ARROW        &none             &none              &kp RIGHT_ARROW   &none       &kp KP_PLUS  &kp N7        &kp N8        &kp N9  &kp KP_MULTIPLY
&mt LEFT_SHIFT J      &kp C_PREVIOUS    &kp C_VOLUME_DOWN  &kp C_VOLUME_UP   &kp C_NEXT  &kp L        &kp KP_MINUS  &kp NUMBER_4  &kp N5  &kp N6           &kp KP_DIVIDE
&kp LS(LEFT_BRACKET)  &kp LEFT_BRACKET  &kp RIGHT_BRACKET  &kp C_PLAY_PAUSE  &kp C_MUTE  &kp KP_DOT   &kp N1        &kp N2        &kp N3  &kp NUMBER_0
                      &tog_of 9         &none              &trans            &trans      &none        &none         &none         &none   &trans           &trans         &trans
            >;
        };

        Emoji-Unused {
            bindings = <
&trans          &trans  &trans  &trans  &trans  &trans  &trans           &trans               &trans         &trans
&kp LEFT_SHIFT  &trans  &trans  &trans  &trans  &trans  &emojiPOC_Macro  &uc UC_WINKING_FACE  &uc 0x1F596 0  &trans  &trans
&trans          &trans  &trans  &trans  &trans  &trans  &trans           &trans               &trans         &trans
                &trans  &trans  &trans  &trans  &trans  &trans           &trans               &trans         &trans  &trans  &trans
            >;
        };

        NAV-Apple {
            display-name = "Nav-Apple";
            bindings = <
&none               &none   &none             &HRM_Tabs_layer_for_tabs  &mo 13    &kp HOME          &kp PAGE_UP    &none     &none     &none
&trans              &trans  &kp LEFT_CONTROL  &kp LALT                  &kp LCMD  &kp LEFT_CONTROL  &none          &kp LEFT  &kp DOWN  &kp UP_ARROW  &kp RIGHT
&kp LC(DOWN_ARROW)  &none   &none             &Flycut_Macro             &none     &kp END           &kp PAGE_DOWN  &none     &none     &none
                    &trans  &trans            &trans                    &trans    &trans            &trans         &trans    &none     &trans        &trans     &trans
            >;
        };

        NAV-Apple-TabsNav_rhsLayoutLhs {
            // F20 shortcuts here is an Amethyst layots selection. See more F20 in other layots

            bindings = <
&none  &none  &kp LC(F20)      &kp LA(LS(F20))  &none        &none            &Web_Page_Back_Macro  &none        &none    &Web_Page_Forward_Macro
&none  &none  &kp LS(LC(F20))  &none            &kp LG(F20)  &kp LG(LS(F20))  &none                 &kp LS(TAB)  &kp TAB  &kp LS(TAB)              &kp TAB
&none  &none  &none            &none            &none        &none            &none                 &none        &none    &none
       &none  &none            &none            &none        &none            &none                 &none        &none    &none                    &none    &none
            >;
        };

        NAV-Apple-BrowserGroupNav {
            bindings = <
&none  &none  &none  &none  &none  &none  &none  &none  &none                      &none
&none  &none  &none  &none  &none  &none  &none  &none  &kp LG(LA(RIGHT_BRACKET))  &kp LG(LA(LEFT_BRACKET))  &none
&none  &none  &none  &none  &none  &none  &none  &none  &none                      &none
       &none  &none  &none  &none  &none  &none  &none  &none                      &none                     &none  &none
            >;
        };

        NAV-Apple-WorkSpaceApps {
            bindings = <
&none  &none  &none  &none  &none  &none  &none  &none          &none  &none
&none  &none  &none  &none  &none  &none  &none  &kp LS(LA(J))  &none  &none  &kp LA(LS(K))
&none  &none  &none  &none  &none  &none  &none  &none          &none  &none
       &none  &none  &none  &none  &none  &none  &none          &none  &none  &none          &none
            >;
        };

        NAV-Apple-AppWindowsCycle {
            // F20 shortcuts here is an Amethyst risizing in split view and so. See more F20 in other layots
            // F11-xx - Switch between Idea/others Focus Editor (E-Editor) & last Tool Window (I-Instruments)
            // App Window Switching:
            //        - on Right: is regular way to switch. There only left and right arrows
            //        - on Left: a) is onehanded switcing, I need when another hand ocupied with mouse. When left hand
            //                      enters this layer with Z, it's motorics is limited and not its not pricise. Thus I
            //                      made for left hand more keys to switch windows than two keys for the right hand.
            //                      They are at positions A=R and S=T.
            //                   b) Plus, one handed swithing with layer is dublicated by AppWindowsSw.. combos.
            //                      Because due to mentioned bad motirics, I often roll keys and have false poritives
            //                      whet A/R/S/T resolved to taps. So I've edded combos wich envolve same keys Z+ARST
            //                      wich handles earlier before false positive tap. In such way if I roll - combos cover
            //                      me and make window swithch. And when I not roll - hold tap layer.
            //         Check commits for denails: e29b7d37b4909a3cf55622e44247970dd6e427ba
            //                                    7906a3aa615c9d78b2ecc074df472e8c55564eea
            //                                    1f7d926b460bcf9e383ee0efb16c31db201d0cb5

            bindings = <
&none  &none              &none              &none          &none          &none  &kp LS(LG(LC(F20)))  &none              &none        &none
&none  &kp LS(LG(GRAVE))  &kp LS(LG(GRAVE))  &kp LG(GRAVE)  &kp LG(GRAVE)  &none  &kp LG(LA(LS(F20)))  &kp LS(LG(GRAVE))  &kp LC(F11)  &kp LC(LS(F11))  &kp LG(GRAVE)
&none  &none              &none              &none          &none          &none  &kp LA(LS(M))        &none              &none        &none
       &none              &none              &none          &none          &none  &none                &none              &none        &none            &kp LA(LS(ENTER))  &none
            >;
        };

        NAV-Ubuntu {
            display-name = "NAV-Ubuntu";
            bindings = <
&none   &none   &none             &none             &mo 18  &kp HOME  &kp PAGE_UP    &none     &none     &none
&trans  &trans  &kp LEFT_CONTROL  &kp LEFT_CONTROL  &mo 26  &none     &none          &kp LEFT  &kp DOWN  &kp UP_ARROW  &kp RIGHT
&none   &none   &none             &none             &none   &kp END   &kp PAGE_DOWN  &none     &none     &none
        &trans  &trans            &trans            &trans  &trans    &trans         &trans    &none     &trans        &trans     &trans
            >;
        };

        NAV-Ubuntu-TabsNav {
            bindings = <
&none  &none  &none  &none  &none  &none  &kp LG(LEFT_BRACKET)  &none            &none  &kp LG(RIGHT_BRACKET)
&none  &none  &none  &none  &none  &none  &none                 &kp LC(LS(TAB))  &none  &none                  &kp LC(TAB)
&none  &none  &none  &none  &none  &none  &none                 &none            &none  &none
       &none  &none  &none  &none  &none  &none                 &none            &none  &none                  &none        &none
            >;
        };

        NAV-NotExist-Ubuntu-BrowGrupNav {
            // On ubuntu I Use only Chrome/Firefox, and both has no option to navigate between tab groups by keyboard

            display-name = "Not-Used. Read comments";
            bindings = <
&none  &none  &none  &none  &none  &none  &none  &none  &none                      &none
&none  &none  &none  &none  &none  &none  &none  &none  &kp LG(LA(RIGHT_BRACKET))  &kp LG(LA(LEFT_BRACKET))  &none
&none  &none  &none  &none  &none  &none  &none  &none  &none                      &none
       &none  &none  &none  &none  &none  &none  &none  &none                      &none                     &none  &none
            >;
        };

        NAV-Ubuntu-WorkSpaceAppCycle {
            bindings = <
&none  &none  &none  &none  &none  &none  &none  &none           &none  &none
&none  &none  &none  &none  &none  &none  &none  &kp LS(ESCAPE)  &none  &none  &kp ESC
&none  &none  &none  &none  &none  &none  &none  &none           &none  &none
       &none  &none  &none  &none  &none  &none  &none           &none  &none  &none    &none
            >;
        };

        NAV-Ubuntu-AppWindowsCycle {
            bindings = <
&none  &none  &none  &none  &none  &none  &none  &none       &none  &none
&none  &none  &none  &none  &none  &none  &none  &kp LS(F6)  &none  &none  &kp F6
&none  &none  &none  &none  &none  &none  &none  &none       &none  &none
       &none  &none  &none  &none  &none  &none  &none       &none  &none  &none   &none
            >;
        };

        mouse_layer {
            //cs4:check:   shortcuts on mouse layer is "get info" on files and open containig dir in music app and are temporary amenity while im reviewing a ton of music

            display-name = "mouse";
            bindings = <
&trans  &trans  &kp LS(LG(R))  &kp LG(I)  &none   &none   &none            &none           &none           &none
&trans  &trans  &kp LG(I)      &trans     &trans  &none   &none            &mmv MOVE_LEFT  &mmv MOVE_DOWN  &mmv MOVE_UP    &mmv MOVE_RIGHT
&none   &trans  &trans         &trans     &none   &none   &msc SCRL_RIGHT  &msc SCRL_UP    &msc SCRL_DOWN  &msc SCRL_LEFT
        &trans  &trans         &trans     &trans  &trans  &trans           &trans          &none           &trans          &mkp LCLK        &mkp RCLK
            >;
        };

        mouse_warp {
            bindings = <
&trans  &trans  &trans  &trans  &trans  &trans  &trans  &trans  &trans  &trans
&trans  &trans  &trans  &trans  &trans  &trans  &trans  &trans  &trans  &trans  &trans
&trans  &trans  &trans  &trans  &trans  &trans  &trans  &trans  &trans  &trans
        &trans  &trans  &trans  &trans  &trans  &trans  &trans  &trans  &trans  &trans  &trans
            >;
        };

        mouse_precision {
            bindings = <
&trans  &trans  &trans  &trans  &trans  &trans  &trans  &trans  &trans  &trans
&trans  &trans  &trans  &trans  &trans  &trans  &trans  &trans  &trans  &trans  &trans
&trans  &trans  &trans  &trans  &trans  &trans  &trans  &trans  &trans  &trans
        &trans  &trans  &trans  &trans  &trans  &trans  &trans  &trans  &trans  &trans  &trans
            >;
        };

        mouse_regular {
            bindings = <
&trans  &trans  &trans  &trans  &trans  &trans  &trans  &trans  &trans  &trans
&trans  &trans  &trans  &trans  &trans  &trans  &trans  &trans  &trans  &trans  &trans
&trans  &trans  &trans  &trans  &trans  &trans  &trans  &trans  &trans  &trans
        &trans  &trans  &trans  &trans  &trans  &trans  &trans  &trans  &trans  &trans  &trans
            >;
        };

        F1_Fx {
            bindings = <
&none   &none              &none                &none        &none                &none   &kp F7  &kp F8  &kp F9  &kp F10
&trans  &hml LEFT_SHIFT F  &hml LEFT_CONTROL H  &hml LALT C  &hml LEFT_COMMAND N  &none   &none   &kp F4  &kp F5  &kp F6   &kp F11
&none   &none              &none                &none        &none                &none   &kp F1  &kp F2  &kp F3  &kp F12
        &trans             &trans               &trans       &trans               &trans  &trans  &trans  &trans  &trans   &trans   &trans
            >;
        };

        NAV-Ubuntu-line-st-end {
            bindings = <
&none  &none  &none  &none  &none  &none  &none  &none     &none  &none
&none  &none  &none  &none  &none  &none  &none  &kp HOME  &none  &none  &kp END
&none  &none  &none  &none  &none  &none  &none  &none     &none  &none
       &none  &none  &none  &none  &none  &none  &none     &none  &none  &none    &none
            >;
        };

        Colemak_Plain_and_Hyper {
            bindings = <
&kp Q           &kp W   &kp F   &kp P   &kp G   &kp J   &kp L   &kp U      &kp Y    &kp LEFT_SHIFT
&kp LEFT_SHIFT  &kp A   &kp R   &kp S   &kp T   &kp D   &kp H   &kp N      &kp E    &kp I           &kp O
&kp Z           &kp X   &kp C   &kp V   &kp B   &kp K   &kp M   &kp COMMA  &kp DOT  &kp FSLH
                &trans  &trans  &trans  &trans  &trans  &trans  &trans     &trans   &trans          &trans  &trans
            >;
        };

        Adjust {
            display-name = "BT, workarounds";
            bindings = <
&tog_on 2  &none       &tog 3      &none       &tog 7        &none         &trans      &Ubuntu_Macro  &none    &tog 25
&none      &none       &bt BT_PRV  &bt BT_NXT  &bt BT_SEL 2  &bt BT_SEL 3  &trans      &trans         &trans   &iPad_Macro  &none
&trans     &trans      &tog_of 2   &kp INSERT  &out OUT_BLE  &none         &Mac_Macro  &trans         &none    &none
           &sys_reset  &none       &none       &none         &none         &none       &sys_reset     &kt F15  &bt BT_CLR   &none  &none
            >;
        };

        Apps {
            bindings = <
&App_Q_TD  &App_W_TD  &App_F_TD  &App_P_TD  &App_G_TD  &App_J_TD  &App_L_TD  &App_U_TD  &App_Y_TD  &none
&none      &App_A_TD  &App_R_TD  &App_S_TD  &App_T_TD  &App_D_TD  &App_H_TD  &App_N_TD  &App_E_TD  &App_I_TD  &App_O_TD
&App_Z_TD  &App_X_TD  &App_C_TD  &App_V_TD  &App_B_TD  &App_K_TD  &App_M_TD  &none      &none      &none
           &none      &none      &none      &none      &none      &none      &none      &none      &none      &none      &none
            >;
        };
    };

    conditional_layers {
        compatible = "zmk,conditional-layers";

        MouseWarpConditional {
            if-layers = <22>;
            then-layer = <21>;
        };

        MousePrecisionConditional {
            if-layers = <23>;
            then-layer = <21>;
        };

        MouseRegularConditional {
            if-layers = <24>;
            then-layer = <21>;
        };

        F1_Fx {
            if-layers = <11 8>;
            then-layer = <25>;
        };
    };
};
